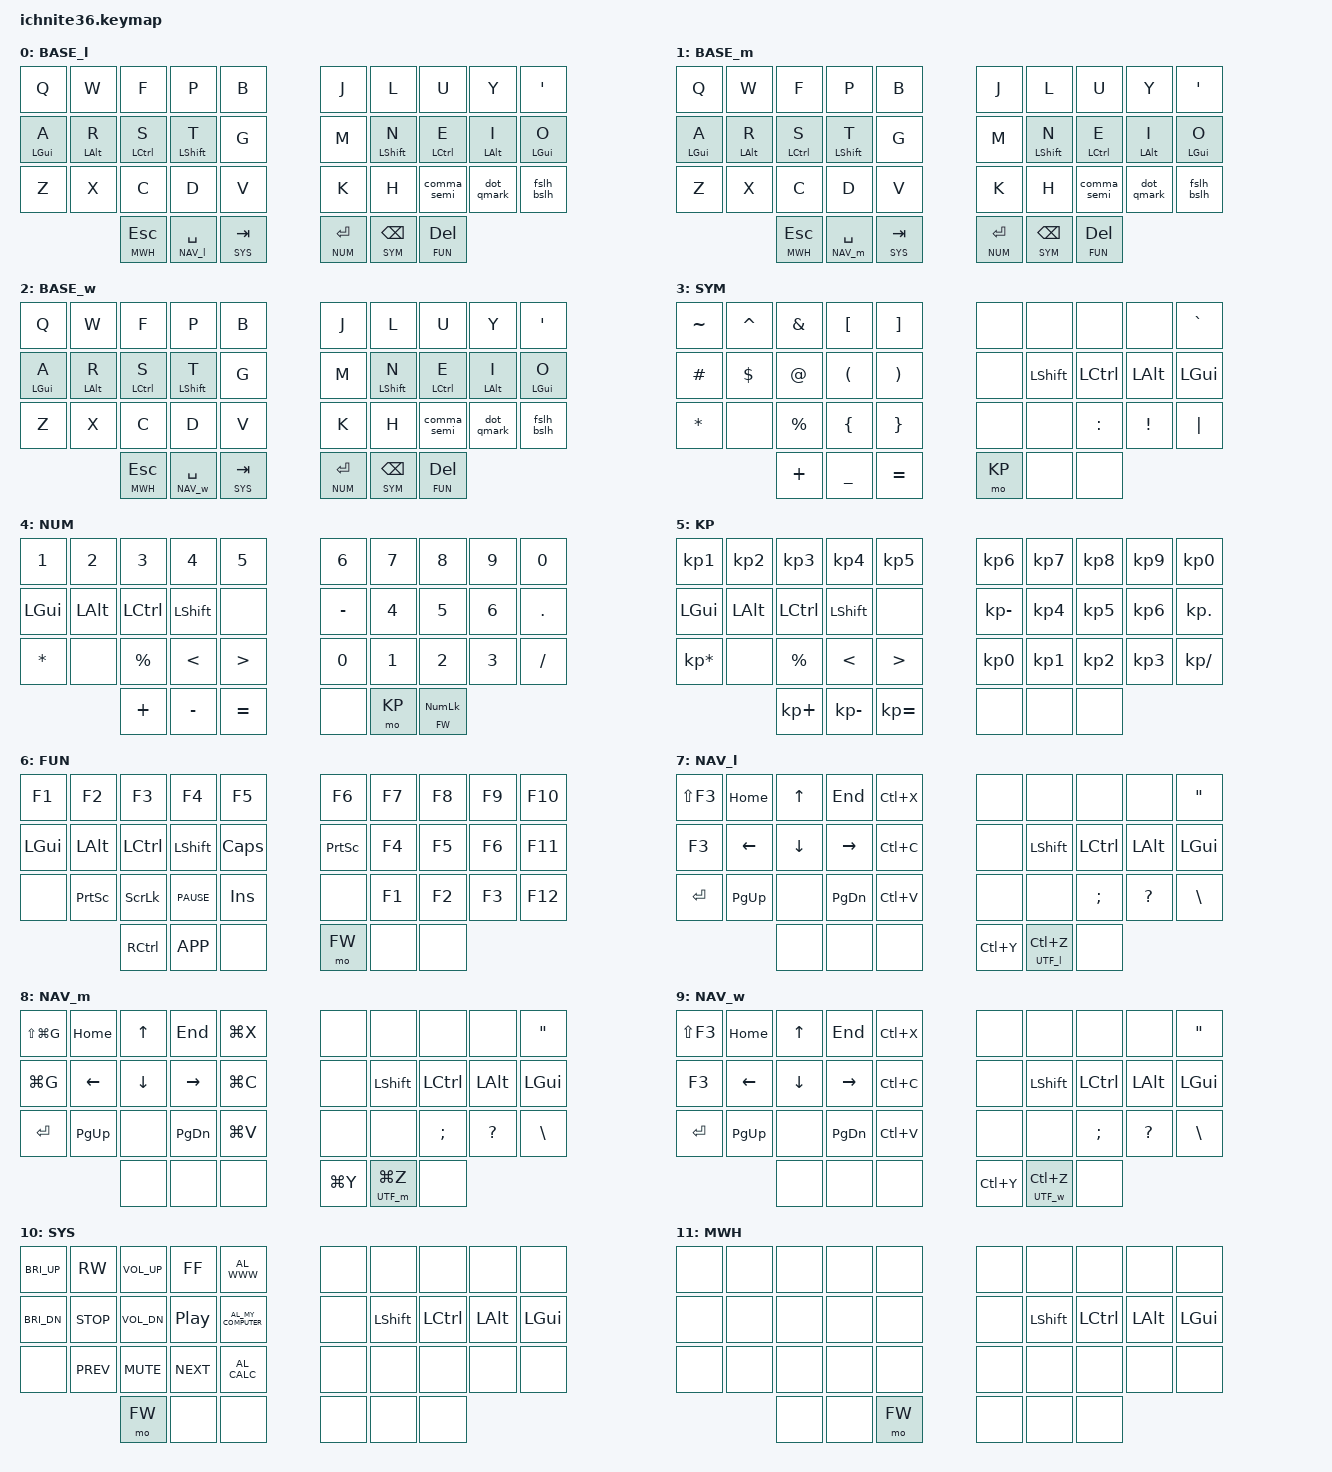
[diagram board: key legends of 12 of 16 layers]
#include <behaviors.dtsi>
#include <dt-bindings/zmk/bt.h>
#include <dt-bindings/zmk/keys.h>
#include <dt-bindings/zmk/outputs.h>

#define BASE_l 0
#define BASE_m 1
#define BASE_w 2
#define SYM 3
#define NUM 4
#define KP 5
#define FUN 6
#define NAV_l 7
#define NAV_m 8
#define NAV_w 9
#define SYS 10
#define MWH 11
#define UTF_l 12
#define UTF_m 13
#define UTF_w 14
#define FW 15

/ {
	chosen {
		zmk,matrix_transform = &default_transform;
	};
	keymap {
		compatible = "zmk,keymap";
		/* Colemak-DHm `base` layer
		┌────────┬────────┬──────────┬────────────┬──────────┐  ┌────────────┬───────────┬──────────┬────────┬────────┐
		│   q    │   w    │    f     │     p      │    b     │  │     j      │     l     │    u     │   y    │  '"    │
		├────────┼────────┼──────────┼────────────┼──────────┤  ├────────────┼───────────┼──────────┼────────┼────────┤
		│ a ⇩CMD │ r ⇩ALT │ s ⇩CTRL  │  t ⇩SHIFT  │    g     │  │     m      │ n ⇩SHIFT  │ e ⇩CTRL  │ i ⇩ALT │ o ⇩CMD │
		├────────┼────────┼──────────┼────────────┼──────────┤  ├────────────┼───────────┼──────────┼────────┼────────┤
		│   z    │   x    │    c     │     d      │    v     │  │     k      │     h     │   ,;     │  .?    │  /\    │
		└────────┴────────┼──────────┼────────────┼──────────┤  ├────────────┼───────────┼──────────┼────────┴────────┘
		                  │ ESC ⇩MWH │ SPACE ⇩NAV │ TAB ⇩SYS │  │ ENTER ⇩NUM │ BSPC ⇩SYM │ DEL ⇩FUN │                  
		                  └──────────┴────────────┴──────────┘  └────────────┴───────────┴──────────┘                   */
		BASE_l {
			bindings = <
			 &kp Q         &kp W         &kp F          &kp P             &kp B            &kp J         &kp L          &kp U          &kp Y         &kp SQT
			 &hrm LGUI A   &hrm LALT R   &hrm LCTRL S   &hrm LSHFT T      &kp G            &kp M         &hrm LSHFT N   &hrm LCTRL E   &hrm LALT I   &hrm LGUI O
			 &kp Z         &kp X         &kp C          &kp D             &kp V            &kp K         &kp H          &comma_semi    &dot_qmark    &fslh_bslh
			                             &lt MWH ESC    &lt NAV_l SPACE   &lt SYS TAB      &lt NUM RET   &lt SYM BSPC   &lt FUN DEL
			>;
		};
		BASE_m {
			bindings = <
			 &kp Q         &kp W         &kp F          &kp P             &kp B            &kp J         &kp L          &kp U          &kp Y         &kp SQT
			 &hrm LGUI A   &hrm LALT R   &hrm LCTRL S   &hrm LSHFT T      &kp G            &kp M         &hrm LSHFT N   &hrm LCTRL E   &hrm LALT I   &hrm LGUI O
			 &kp Z         &kp X         &kp C          &kp D             &kp V            &kp K         &kp H          &comma_semi    &dot_qmark    &fslh_bslh
			                             &lt MWH ESC    &lt NAV_m SPACE   &lt SYS TAB      &lt NUM RET   &lt SYM BSPC   &lt FUN DEL
			>;
		};
		BASE_w {
			bindings = <
			 &kp Q         &kp W         &kp F          &kp P             &kp B            &kp J         &kp L          &kp U          &kp Y         &kp SQT
			 &hrm LGUI A   &hrm LALT R   &hrm LCTRL S   &hrm LSHFT T      &kp G            &kp M         &hrm LSHFT N   &hrm LCTRL E   &hrm LALT I   &hrm LGUI O
			 &kp Z         &kp X         &kp C          &kp D             &kp V            &kp K         &kp H          &comma_semi    &dot_qmark    &fslh_bslh
			                             &lt MWH ESC    &lt NAV_w SPACE   &lt SYS TAB      &lt NUM RET   &lt SYM BSPC   &lt FUN DEL
			>;
		};
		/* Symbols
		┌───────┬───────┬───────┬───────┬───────┐  ┌───────┬───────┬───────┬───────┬───────┐
		│   ~   │   ^   │   &   │   [   │   ]   │  │       │       │       │       │   `   │
		├───────┼───────┼───────┼───────┼───────┤  ├───────┼───────┼───────┼───────┼───────┤
		│   #   │   $   │   @   │   (   │   )   │  │       │ SHIFT │ CTRL  │  ALT  │  CMD  │
		├───────┼───────┼───────┼───────┼───────┤  ├───────┼───────┼───────┼───────┼───────┤
		│   *   │       │   %   │   {   │   }   │  │       │       │   :   │   !   │ PIPE  │
		└───────┴───────┼───────┼───────┼───────┤  ├───────┼───────┼───────┼───────┴───────┘
		                │   +   │   _   │   =   │  │  ⇩KP  │       │       │                
		                └───────┴───────┴───────┘  └───────┴───────┴───────┘                 */
		SYM {
			bindings = <
			 &kp TILDE   &kp CARET   &kp AMPS    &kp LBKT    &kp RBKT       &none    &none       &none       &none      &kp GRAVE
			 &kp HASH    &kp DLLR    &kp AT      &kp LPAR    &kp RPAR       &none    &kp LSHFT   &kp LCTRL   &kp LALT   &kp LGUI
			 &kp STAR    &none       &kp PRCNT   &kp LBRC    &kp RBRC       &none    &none       &kp COLON   &kp EXCL   &kp PIPE
			                         &kp PLUS    &kp UNDER   &kp EQUAL      &mo KP   &none       &none
			>;
		};
		/* Numerals
		┌───────┬───────┬───────┬───────┬───────┐  ┌───────┬───────┬───────────┬───────┬───────┐
		│   1   │   2   │   3   │   4   │   5   │  │   6   │   7   │     8     │   9   │   0   │
		├───────┼───────┼───────┼───────┼───────┤  ├───────┼───────┼───────────┼───────┼───────┤
		│  CMD  │  ALT  │ CTRL  │ SHIFT │       │  │   -   │   4   │     5     │   6   │   .   │
		├───────┼───────┼───────┼───────┼───────┤  ├───────┼───────┼───────────┼───────┼───────┤
		│   *   │       │   %   │   <   │   >   │  │   0   │   1   │     2     │   3   │   /   │
		└───────┴───────┼───────┼───────┼───────┤  ├───────┼───────┼───────────┼───────┴───────┘
		                │   +   │   -   │   =   │  │       │  ⇩KP  │ NLOCK ⇩FW │                
		                └───────┴───────┴───────┘  └───────┴───────┴───────────┘                 */
		NUM {
			bindings = <
			 &kp N1     &kp N2     &kp N3      &kp N4      &kp N5         &kp N6      &kp N7   &kp N8          &kp N9   &kp N0
			 &kp LGUI   &kp LALT   &kp LCTRL   &kp LSHFT   &none          &kp MINUS   &kp N4   &kp N5          &kp N6   &kp DOT
			 &kp STAR   &none      &kp PRCNT   &kp LT      &kp GT         &kp N0      &kp N1   &kp N2          &kp N3   &kp FSLH
			                       &kp PLUS    &kp MINUS   &kp EQUAL      &none       &mo KP   &lt FW KP_NUM
			>;
		};
		/* Keypad numerals on `NUM+SYM` combo
		┌───────┬───────┬───────┬───────┬───────┐  ┌───────┬───────┬───────┬───────┬───────┐
		│  KP1  │  KP2  │  KP3  │  KP4  │  KP5  │  │  KP6  │  KP7  │  KP8  │  KP9  │  KP0  │
		├───────┼───────┼───────┼───────┼───────┤  ├───────┼───────┼───────┼───────┼───────┤
		│  CMD  │  ALT  │ CTRL  │ SHIFT │       │  │  KP-  │  KP4  │  KP5  │  KP6  │  KP.  │
		├───────┼───────┼───────┼───────┼───────┤  ├───────┼───────┼───────┼───────┼───────┤
		│  KP*  │       │   %   │   <   │   >   │  │  KP0  │  KP1  │  KP2  │  KP3  │  KP/  │
		└───────┴───────┼───────┼───────┼───────┤  ├───────┼───────┼───────┼───────┴───────┘
		                │  KP+  │  KP-  │  KP=  │  │       │       │       │                
		                └───────┴───────┴───────┘  └───────┴───────┴───────┘                 */
		KP {
			bindings = <
			 &kp KP_N1         &kp KP_N2   &kp KP_N3     &kp KP_N4      &kp KP_N5         &kp KP_N6      &kp KP_N7   &kp KP_N8   &kp KP_N9   &kp KP_N0
			 &kp LGUI          &kp LALT    &kp LCTRL     &kp LSHFT      &none             &kp KP_MINUS   &kp KP_N4   &kp KP_N5   &kp KP_N6   &kp KP_DOT
			 &kp KP_MULTIPLY   &none       &kp PRCNT     &kp LT         &kp GT            &kp KP_N0      &kp KP_N1   &kp KP_N2   &kp KP_N3   &kp KP_SLASH
			                               &kp KP_PLUS   &kp KP_MINUS   &kp KP_EQUAL      &none          &none       &none
			>;
		};
		/* Function keys
		┌───────┬───────┬───────┬───────┬───────┐  ┌───────┬───────┬───────┬───────┬───────┐
		│  F1   │  F2   │  F3   │  F4   │  F5   │  │  F6   │  F7   │  F8   │  F9   │  F10  │
		├───────┼───────┼───────┼───────┼───────┤  ├───────┼───────┼───────┼───────┼───────┤
		│  CMD  │  ALT  │ CTRL  │ SHIFT │ CAPS  │  │ PSCR  │  F4   │  F5   │  F6   │  F11  │
		├───────┼───────┼───────┼───────┼───────┤  ├───────┼───────┼───────┼───────┼───────┤
		│       │ PSCR  │ SLOCK │ PAUSE │  INS  │  │       │  F1   │  F2   │  F3   │  F12  │
		└───────┴───────┼───────┼───────┼───────┤  ├───────┼───────┼───────┼───────┴───────┘
		                │ rCTRL │  APP  │       │  │  ⇩FW  │       │       │                
		                └───────┴───────┴───────┘  └───────┴───────┴───────┘                 */
		FUN {
			bindings = <
			 &kp F1     &kp F2      &kp F3      &kp F4        &kp F5        &kp F6      &kp F7   &kp F8   &kp F9   &kp F10
			 &kp LGUI   &kp LALT    &kp LCTRL   &kp LSHFT     &kp CAPS      &kp PSCRN   &kp F4   &kp F5   &kp F6   &kp F11
			 &none      &kp PSCRN   &kp SLCK    &kp C_PAUSE   &kp INS       &none       &kp F1   &kp F2   &kp F3   &kp F12
			                        &kp RCTRL   &kp K_APP     &none         &mo FW      &none    &none
			>;
		};
		/* Navigation
		┌───────┬───────┬───────┬───────┬───────┐  ┌───────┬───────────┬───────┬───────┬───────┐
		│ FIND- │ HOME  │  UP   │  END  │  CUT  │  │       │           │       │       │   "   │
		├───────┼───────┼───────┼───────┼───────┤  ├───────┼───────────┼───────┼───────┼───────┤
		│ FIND+ │ LEFT  │ DOWN  │ RIGHT │ COPY  │  │       │   SHIFT   │ CTRL  │  ALT  │  CMD  │
		├───────┼───────┼───────┼───────┼───────┤  ├───────┼───────────┼───────┼───────┼───────┤
		│ ENTER │ PG_UP │       │ PG_DN │ PASTE │  │       │           │   ;   │   ?   │   \   │
		└───────┴───────┼───────┼───────┼───────┤  ├───────┼───────────┼───────┼───────┴───────┘
		                │       │       │       │  │ REDO  │ UNDO ⇩UTF │       │                
		                └───────┴───────┴───────┘  └───────┴───────────┴───────┘                 */
		NAV_l {
			bindings = <
			 &kp LS(F3)   &kp HOME    &kp UP     &kp END     &kp LC(X)      &none       &none             &none       &none       &kp DQT
			 &kp F3       &kp LEFT    &kp DOWN   &kp RIGHT   &kp LC(C)      &none       &kp LSHFT         &kp LCTRL   &kp LALT    &kp LGUI
			 &kp RET      &kp PG_UP   &none      &kp PG_DN   &kp LC(V)      &none       &none             &kp SEMI    &kp QMARK   &kp BSLH
			                          &none      &none       &none          &kp LC(Y)   &lt UTF_l LC(Z)   &none
			>;
		};
		NAV_m {
			bindings = <
			 &kp LS(LG(G))   &kp HOME    &kp UP     &kp END     &kp LG(X)      &none       &none             &none       &none       &kp DQT
			 &kp LG(G)       &kp LEFT    &kp DOWN   &kp RIGHT   &kp LG(C)      &none       &kp LSHFT         &kp LCTRL   &kp LALT    &kp LGUI
			 &kp RET         &kp PG_UP   &none      &kp PG_DN   &kp LG(V)      &none       &none             &kp SEMI    &kp QMARK   &kp BSLH
			                             &none      &none       &none          &kp LG(Y)   &lt UTF_m LG(Z)   &none
			>;
		};
		NAV_w {
			bindings = <
			 &kp LS(F3)   &kp HOME    &kp UP     &kp END     &kp LC(X)      &none       &none             &none       &none       &kp DQT
			 &kp F3       &kp LEFT    &kp DOWN   &kp RIGHT   &kp LC(C)      &none       &kp LSHFT         &kp LCTRL   &kp LALT    &kp LGUI
			 &kp RET      &kp PG_UP   &none      &kp PG_DN   &kp LC(V)      &none       &none             &kp SEMI    &kp QMARK   &kp BSLH
			                          &none      &none       &none          &kp LC(Y)   &lt UTF_w LC(Z)   &none
			>;
		};
		/* System/media keys
		┌───────┬───────┬───────┬───────┬────────┐  ┌───────┬───────┬───────┬───────┬───────┐
		│ BRI+  │  RWD  │ VOL+  │  FFW  │  WWW   │  │       │       │       │       │       │
		├───────┼───────┼───────┼───────┼────────┤  ├───────┼───────┼───────┼───────┼───────┤
		│ BRI-  │ STOP  │ VOL-  │ PLAY  │ MYCOMP │  │       │ SHIFT │ CTRL  │  ALT  │  CMD  │
		├───────┼───────┼───────┼───────┼────────┤  ├───────┼───────┼───────┼───────┼───────┤
		│       │ PREV  │ MUTE  │ NEXT  │ CALC   │  │       │       │       │       │       │
		└───────┴───────┼───────┼───────┼────────┤  ├───────┼───────┼───────┼───────┴───────┘
		                │  ⇩FW  │       │        │  │       │       │       │                
		                └───────┴───────┴────────┘  └───────┴───────┴───────┘                 */
		SYS {
			bindings = <
			 &kp C_BRI_UP   &kp C_RW     &kp C_VOL_UP   &kp C_FF     &kp C_AL_WWW              &none   &none       &none       &none      &none
			 &kp C_BRI_DN   &kp C_STOP   &kp C_VOL_DN   &kp C_PP     &kp C_AL_MY_COMPUTER      &none   &kp LSHFT   &kp LCTRL   &kp LALT   &kp LGUI
			 &none          &kp C_PREV   &kp C_MUTE     &kp C_NEXT   &kp C_AL_CALC             &none   &none       &none       &none      &none
			                             &mo FW         &none        &none                     &none   &none       &none
			>;
		};
		/* Mouse scrolling
		┌───────┬───────┬───────┬───────┬───────┐  ┌───────┬───────┬───────┬───────┬───────┐
		│       │       │ WH_U  │       │       │  │       │       │       │       │       │
		├───────┼───────┼───────┼───────┼───────┤  ├───────┼───────┼───────┼───────┼───────┤
		│       │ WH_L  │ WH_D  │ WH_R  │       │  │       │ SHIFT │ CTRL  │  ALT  │  CMD  │
		├───────┼───────┼───────┼───────┼───────┤  ├───────┼───────┼───────┼───────┼───────┤
		│       │       │       │       │       │  │       │       │       │       │       │
		└───────┴───────┼───────┼───────┼───────┤  ├───────┼───────┼───────┼───────┴───────┘
		                │       │       │  ⇩FW  │  │       │       │       │                
		                └───────┴───────┴───────┘  └───────┴───────┴───────┘                 */
		MWH {
			bindings = <
			 &none   &none   &none   &none   &none       &none   &none       &none       &none      &none
			 &none   &none   &none   &none   &none       &none   &kp LSHFT   &kp LCTRL   &kp LALT   &kp LGUI
			 &none   &none   &none   &none   &none       &none   &none       &none       &none      &none
			                 &none   &none   &mo FW      &none   &none       &none
			>;
		};
		/* Unicode Symbols on `NAV>SYM`
		┌───────┬───────┬───────┬───────┬───────┐  ┌───────┬───────┬───────┬───────┬───────┐
		│       │       │   °   │   √   │       │  │       │   μ   │   Δ   │   ε   │       │
		├───────┼───────┼───────┼───────┼───────┤  ├───────┼───────┼───────┼───────┼───────┤
		│   ∞   │   €   │       │   ²   │   ³   │  │       │   π   │   φ   │   θ   │       │
		├───────┼───────┼───────┼───────┼───────┤  ├───────┼───────┼───────┼───────┼───────┤
		│   ×   │       │   ≈   │   ≤   │   ≥   │  │   λ   │   α   │   β   │   ¿   │   ÷   │
		└───────┴───────┼───────┼───────┼───────┤  ├───────┼───────┼───────┼───────┴───────┘
		                │   ±   │       │   ≠   │  │       │       │       │                
		                └───────┴───────┴───────┘  └───────┴───────┴───────┘                 */
		UTF_l {
			bindings = <
			 &none      &none      &u00b0_L   &u221a_L   &none         &none      &u03bc_L   &u0394_L   &u03b5_L   &none
			 &u221e_L   &u20ac_L   &none      &u00b2_L   &u00b3_L      &none      &u03c0_L   &u03c6_L   &u03b8_L   &none
			 &u00d7_L   &none      &u2248_L   &u2264_L   &u2265_L      &u03bb_L   &u03b1_L   &u03b2_L   &u00bf_L   &u00f7_L
			                       &u00b1_L   &none      &u2260_L      &none      &none      &none
			>;
		};
		UTF_m {
			bindings = <
			 &none      &none      &u00b0_M   &u221a_M   &none         &none      &u03bc_M   &u0394_M   &u03b5_M   &none
			 &u221e_M   &u20ac_M   &none      &u00b2_M   &u00b3_M      &none      &u03c0_M   &u03c6_M   &u03b8_M   &none
			 &u00d7_M   &none      &u2248_M   &u2264_M   &u2265_M      &u03bb_M   &u03b1_M   &u03b2_M   &u00bf_M   &u00f7_M
			                       &u00b1_M   &none      &u2260_M      &none      &none      &none
			>;
		};
		UTF_w {
			bindings = <
			 &none      &none      &u00b0_W   &u221a_W   &none         &none      &u03bc_W   &u0394_W   &u03b5_W   &none
			 &u221e_W   &u20ac_W   &none      &u00b2_W   &u00b3_W      &none      &u03c0_W   &u03c6_W   &u03b8_W   &none
			 &u00d7_W   &none      &u2248_W   &u2264_W   &u2265_W      &u03bb_W   &u03b1_W   &u03b2_W   &u00bf_W   &u00f7_W
			                       &u00b1_W   &none      &u2260_W      &none      &none      &none
			>;
		};
		/* Firmware on `NUM+FUN` or `MWH+SYS` combo
		┌───────┬───────┬───────┬────────┬───────┐  ┌───────┬───────┬───────┬───────┬───────┐
		│  BT1  │  BT2  │  BT3  │  BT4   │  BT5  │  │  USB  │       │       │       │ BTCLR │
		├───────┼───────┼───────┼────────┼───────┤  ├───────┼───────┼───────┼───────┼───────┤
		│       │ @win  │ @mac  │ @linux │       │  │       │       │       │       │       │
		├───────┼───────┼───────┼────────┼───────┤  ├───────┼───────┼───────┼───────┼───────┤
		│       │       │       │        │       │  │       │       │       │       │       │
		└───────┴───────┼───────┼────────┼───────┤  ├───────┼───────┼───────┼───────┴───────┘
		                │ DEBUG │ RESET  │ BOOTL │  │ BOOTL │ RESET │ DEBUG │                
		                └───────┴────────┴───────┘  └───────┴───────┴───────┘                 */
		FW {
			bindings = <
			 &bt1    &bt2         &bt3         &bt4         &bt5             &out OUT_USB   &none    &none   &none   &bt BT_CLR
			 &none   &to BASE_w   &to BASE_m   &to BASE_l   &none            &none          &none    &none   &none   &none
			 &none   &none        &none        &none        &none            &none          &none    &none   &none   &none
			                      &none        &reset       &bootloader      &bootloader    &reset   &none
			>;
		};
	};
	behaviors {
		hrm: modtap {
			compatible = "zmk,behavior-hold-tap";
			label = "HOMEROWMOD";
			#binding-cells = <2>;
			bindings = <&kp>, <&kp>;
		};
		comma_semi: comma_semi {
			compatible = "zmk,behavior-mod-morph";
			label = "shift-morph COMMA SEMI";
			#binding-cells = <0>;
			bindings = <&kp COMMA>, <&kp SEMI>;
			mods = <(MOD_LSFT|MOD_RSFT)>;
		};
		dot_qmark: dot_qmark {
			compatible = "zmk,behavior-mod-morph";
			label = "shift-morph DOT QMARK";
			#binding-cells = <0>;
			bindings = <&kp DOT>, <&kp QMARK>;
			mods = <(MOD_LSFT|MOD_RSFT)>;
		};
		fslh_bslh: fslh_bslh {
			compatible = "zmk,behavior-mod-morph";
			label = "shift-morph FSLH BSLH";
			#binding-cells = <0>;
			bindings = <&kp FSLH>, <&kp BSLH>;
			mods = <(MOD_LSFT|MOD_RSFT)>;
		};
		u00b0_L: u00b0_L {
			compatible = "zmk,behavior-macro";
			label = "Linux ° macro";
			#binding-cells = <0>;
			bindings = <&macro_tap &kp LC(LS(U)) &kp N0 &kp N0 &kp B &kp N0 &kp SPACE>;
			tap-ms = <30>;
			wait-ms = <0>;
		};
		u221a_L: u221a_L {
			compatible = "zmk,behavior-macro";
			label = "Linux √ macro";
			#binding-cells = <0>;
			bindings = <&macro_tap &kp LC(LS(U)) &kp N2 &kp N2 &kp N1 &kp A &kp SPACE>;
			tap-ms = <30>;
			wait-ms = <0>;
		};
		u03bc_L: u03bc_L {
			compatible = "zmk,behavior-macro";
			label = "Linux μ macro";
			#binding-cells = <0>;
			bindings = <&macro_tap &kp LC(LS(U)) &kp N0 &kp N3 &kp B &kp C &kp SPACE>;
			tap-ms = <30>;
			wait-ms = <0>;
		};
		u0394_L: u0394_L {
			compatible = "zmk,behavior-macro";
			label = "Linux Δ macro";
			#binding-cells = <0>;
			bindings = <&macro_tap &kp LC(LS(U)) &kp N0 &kp N3 &kp N9 &kp N4 &kp SPACE>;
			tap-ms = <30>;
			wait-ms = <0>;
		};
		u03b5_L: u03b5_L {
			compatible = "zmk,behavior-macro";
			label = "Linux ε macro";
			#binding-cells = <0>;
			bindings = <&macro_tap &kp LC(LS(U)) &kp N0 &kp N3 &kp B &kp N5 &kp SPACE>;
			tap-ms = <30>;
			wait-ms = <0>;
		};
		u221e_L: u221e_L {
			compatible = "zmk,behavior-macro";
			label = "Linux ∞ macro";
			#binding-cells = <0>;
			bindings = <&macro_tap &kp LC(LS(U)) &kp N2 &kp N2 &kp N1 &kp E &kp SPACE>;
			tap-ms = <30>;
			wait-ms = <0>;
		};
		u20ac_L: u20ac_L {
			compatible = "zmk,behavior-macro";
			label = "Linux € macro";
			#binding-cells = <0>;
			bindings = <&macro_tap &kp LC(LS(U)) &kp N2 &kp N0 &kp A &kp C &kp SPACE>;
			tap-ms = <30>;
			wait-ms = <0>;
		};
		u00b2_L: u00b2_L {
			compatible = "zmk,behavior-macro";
			label = "Linux ² macro";
			#binding-cells = <0>;
			bindings = <&macro_tap &kp LC(LS(U)) &kp N0 &kp N0 &kp B &kp N2 &kp SPACE>;
			tap-ms = <30>;
			wait-ms = <0>;
		};
		u00b3_L: u00b3_L {
			compatible = "zmk,behavior-macro";
			label = "Linux ³ macro";
			#binding-cells = <0>;
			bindings = <&macro_tap &kp LC(LS(U)) &kp N0 &kp N0 &kp B &kp N3 &kp SPACE>;
			tap-ms = <30>;
			wait-ms = <0>;
		};
		u03c0_L: u03c0_L {
			compatible = "zmk,behavior-macro";
			label = "Linux π macro";
			#binding-cells = <0>;
			bindings = <&macro_tap &kp LC(LS(U)) &kp N0 &kp N3 &kp C &kp N0 &kp SPACE>;
			tap-ms = <30>;
			wait-ms = <0>;
		};
		u03c6_L: u03c6_L {
			compatible = "zmk,behavior-macro";
			label = "Linux φ macro";
			#binding-cells = <0>;
			bindings = <&macro_tap &kp LC(LS(U)) &kp N0 &kp N3 &kp C &kp N6 &kp SPACE>;
			tap-ms = <30>;
			wait-ms = <0>;
		};
		u03b8_L: u03b8_L {
			compatible = "zmk,behavior-macro";
			label = "Linux θ macro";
			#binding-cells = <0>;
			bindings = <&macro_tap &kp LC(LS(U)) &kp N0 &kp N3 &kp B &kp N8 &kp SPACE>;
			tap-ms = <30>;
			wait-ms = <0>;
		};
		u00d7_L: u00d7_L {
			compatible = "zmk,behavior-macro";
			label = "Linux × macro";
			#binding-cells = <0>;
			bindings = <&macro_tap &kp LC(LS(U)) &kp N0 &kp N0 &kp D &kp N7 &kp SPACE>;
			tap-ms = <30>;
			wait-ms = <0>;
		};
		u2248_L: u2248_L {
			compatible = "zmk,behavior-macro";
			label = "Linux ≈ macro";
			#binding-cells = <0>;
			bindings = <&macro_tap &kp LC(LS(U)) &kp N2 &kp N2 &kp N4 &kp N8 &kp SPACE>;
			tap-ms = <30>;
			wait-ms = <0>;
		};
		u2264_L: u2264_L {
			compatible = "zmk,behavior-macro";
			label = "Linux ≤ macro";
			#binding-cells = <0>;
			bindings = <&macro_tap &kp LC(LS(U)) &kp N2 &kp N2 &kp N6 &kp N4 &kp SPACE>;
			tap-ms = <30>;
			wait-ms = <0>;
		};
		u2265_L: u2265_L {
			compatible = "zmk,behavior-macro";
			label = "Linux ≥ macro";
			#binding-cells = <0>;
			bindings = <&macro_tap &kp LC(LS(U)) &kp N2 &kp N2 &kp N6 &kp N5 &kp SPACE>;
			tap-ms = <30>;
			wait-ms = <0>;
		};
		u03bb_L: u03bb_L {
			compatible = "zmk,behavior-macro";
			label = "Linux λ macro";
			#binding-cells = <0>;
			bindings = <&macro_tap &kp LC(LS(U)) &kp N0 &kp N3 &kp B &kp B &kp SPACE>;
			tap-ms = <30>;
			wait-ms = <0>;
		};
		u03b1_L: u03b1_L {
			compatible = "zmk,behavior-macro";
			label = "Linux α macro";
			#binding-cells = <0>;
			bindings = <&macro_tap &kp LC(LS(U)) &kp N0 &kp N3 &kp B &kp N1 &kp SPACE>;
			tap-ms = <30>;
			wait-ms = <0>;
		};
		u03b2_L: u03b2_L {
			compatible = "zmk,behavior-macro";
			label = "Linux β macro";
			#binding-cells = <0>;
			bindings = <&macro_tap &kp LC(LS(U)) &kp N0 &kp N3 &kp B &kp N2 &kp SPACE>;
			tap-ms = <30>;
			wait-ms = <0>;
		};
		u00bf_L: u00bf_L {
			compatible = "zmk,behavior-macro";
			label = "Linux ¿ macro";
			#binding-cells = <0>;
			bindings = <&macro_tap &kp LC(LS(U)) &kp N0 &kp N0 &kp B &kp F &kp SPACE>;
			tap-ms = <30>;
			wait-ms = <0>;
		};
		u00f7_L: u00f7_L {
			compatible = "zmk,behavior-macro";
			label = "Linux ÷ macro";
			#binding-cells = <0>;
			bindings = <&macro_tap &kp LC(LS(U)) &kp N0 &kp N0 &kp F &kp N7 &kp SPACE>;
			tap-ms = <30>;
			wait-ms = <0>;
		};
		u00b1_L: u00b1_L {
			compatible = "zmk,behavior-macro";
			label = "Linux ± macro";
			#binding-cells = <0>;
			bindings = <&macro_tap &kp LC(LS(U)) &kp N0 &kp N0 &kp B &kp N1 &kp SPACE>;
			tap-ms = <30>;
			wait-ms = <0>;
		};
		u2260_L: u2260_L {
			compatible = "zmk,behavior-macro";
			label = "Linux ≠ macro";
			#binding-cells = <0>;
			bindings = <&macro_tap &kp LC(LS(U)) &kp N2 &kp N2 &kp N6 &kp N0 &kp SPACE>;
			tap-ms = <30>;
			wait-ms = <0>;
		};
		u00b0_M: u00b0_M {
			compatible = "zmk,behavior-macro";
			label = "Mac ° macro";
			#binding-cells = <0>;
			bindings = <&macro_press &kp LALT>, <&macro_tap &kp N0 &kp N0 &kp B &kp N0>, <&macro_release &kp LALT>;
			tap-ms = <30>;
			wait-ms = <30>;
		};
		u221a_M: u221a_M {
			compatible = "zmk,behavior-macro";
			label = "Mac √ macro";
			#binding-cells = <0>;
			bindings = <&macro_press &kp LALT>, <&macro_tap &kp N2 &kp N2 &kp N1 &kp A>, <&macro_release &kp LALT>;
			tap-ms = <30>;
			wait-ms = <30>;
		};
		u03bc_M: u03bc_M {
			compatible = "zmk,behavior-macro";
			label = "Mac μ macro";
			#binding-cells = <0>;
			bindings = <&macro_press &kp LALT>, <&macro_tap &kp N0 &kp N3 &kp B &kp C>, <&macro_release &kp LALT>;
			tap-ms = <30>;
			wait-ms = <30>;
		};
		u0394_M: u0394_M {
			compatible = "zmk,behavior-macro";
			label = "Mac Δ macro";
			#binding-cells = <0>;
			bindings = <&macro_press &kp LALT>, <&macro_tap &kp N0 &kp N3 &kp N9 &kp N4>, <&macro_release &kp LALT>;
			tap-ms = <30>;
			wait-ms = <30>;
		};
		u03b5_M: u03b5_M {
			compatible = "zmk,behavior-macro";
			label = "Mac ε macro";
			#binding-cells = <0>;
			bindings = <&macro_press &kp LALT>, <&macro_tap &kp N0 &kp N3 &kp B &kp N5>, <&macro_release &kp LALT>;
			tap-ms = <30>;
			wait-ms = <30>;
		};
		u221e_M: u221e_M {
			compatible = "zmk,behavior-macro";
			label = "Mac ∞ macro";
			#binding-cells = <0>;
			bindings = <&macro_press &kp LALT>, <&macro_tap &kp N2 &kp N2 &kp N1 &kp E>, <&macro_release &kp LALT>;
			tap-ms = <30>;
			wait-ms = <30>;
		};
		u20ac_M: u20ac_M {
			compatible = "zmk,behavior-macro";
			label = "Mac € macro";
			#binding-cells = <0>;
			bindings = <&macro_press &kp LALT>, <&macro_tap &kp N2 &kp N0 &kp A &kp C>, <&macro_release &kp LALT>;
			tap-ms = <30>;
			wait-ms = <30>;
		};
		u00b2_M: u00b2_M {
			compatible = "zmk,behavior-macro";
			label = "Mac ² macro";
			#binding-cells = <0>;
			bindings = <&macro_press &kp LALT>, <&macro_tap &kp N0 &kp N0 &kp B &kp N2>, <&macro_release &kp LALT>;
			tap-ms = <30>;
			wait-ms = <30>;
		};
		u00b3_M: u00b3_M {
			compatible = "zmk,behavior-macro";
			label = "Mac ³ macro";
			#binding-cells = <0>;
			bindings = <&macro_press &kp LALT>, <&macro_tap &kp N0 &kp N0 &kp B &kp N3>, <&macro_release &kp LALT>;
			tap-ms = <30>;
			wait-ms = <30>;
		};
		u03c0_M: u03c0_M {
			compatible = "zmk,behavior-macro";
			label = "Mac π macro";
			#binding-cells = <0>;
			bindings = <&macro_press &kp LALT>, <&macro_tap &kp N0 &kp N3 &kp C &kp N0>, <&macro_release &kp LALT>;
			tap-ms = <30>;
			wait-ms = <30>;
		};
		u03c6_M: u03c6_M {
			compatible = "zmk,behavior-macro";
			label = "Mac φ macro";
			#binding-cells = <0>;
			bindings = <&macro_press &kp LALT>, <&macro_tap &kp N0 &kp N3 &kp C &kp N6>, <&macro_release &kp LALT>;
			tap-ms = <30>;
			wait-ms = <30>;
		};
		u03b8_M: u03b8_M {
			compatible = "zmk,behavior-macro";
			label = "Mac θ macro";
			#binding-cells = <0>;
			bindings = <&macro_press &kp LALT>, <&macro_tap &kp N0 &kp N3 &kp B &kp N8>, <&macro_release &kp LALT>;
			tap-ms = <30>;
			wait-ms = <30>;
		};
		u00d7_M: u00d7_M {
			compatible = "zmk,behavior-macro";
			label = "Mac × macro";
			#binding-cells = <0>;
			bindings = <&macro_press &kp LALT>, <&macro_tap &kp N0 &kp N0 &kp D &kp N7>, <&macro_release &kp LALT>;
			tap-ms = <30>;
			wait-ms = <30>;
		};
		u2248_M: u2248_M {
			compatible = "zmk,behavior-macro";
			label = "Mac ≈ macro";
			#binding-cells = <0>;
			bindings = <&macro_press &kp LALT>, <&macro_tap &kp N2 &kp N2 &kp N4 &kp N8>, <&macro_release &kp LALT>;
			tap-ms = <30>;
			wait-ms = <30>;
		};
		u2264_M: u2264_M {
			compatible = "zmk,behavior-macro";
			label = "Mac ≤ macro";
			#binding-cells = <0>;
			bindings = <&macro_press &kp LALT>, <&macro_tap &kp N2 &kp N2 &kp N6 &kp N4>, <&macro_release &kp LALT>;
			tap-ms = <30>;
			wait-ms = <30>;
		};
		u2265_M: u2265_M {
			compatible = "zmk,behavior-macro";
			label = "Mac ≥ macro";
			#binding-cells = <0>;
			bindings = <&macro_press &kp LALT>, <&macro_tap &kp N2 &kp N2 &kp N6 &kp N5>, <&macro_release &kp LALT>;
			tap-ms = <30>;
			wait-ms = <30>;
		};
		u03bb_M: u03bb_M {
			compatible = "zmk,behavior-macro";
			label = "Mac λ macro";
			#binding-cells = <0>;
			bindings = <&macro_press &kp LALT>, <&macro_tap &kp N0 &kp N3 &kp B &kp B>, <&macro_release &kp LALT>;
			tap-ms = <30>;
			wait-ms = <30>;
		};
		u03b1_M: u03b1_M {
			compatible = "zmk,behavior-macro";
			label = "Mac α macro";
			#binding-cells = <0>;
			bindings = <&macro_press &kp LALT>, <&macro_tap &kp N0 &kp N3 &kp B &kp N1>, <&macro_release &kp LALT>;
			tap-ms = <30>;
			wait-ms = <30>;
		};
		u03b2_M: u03b2_M {
			compatible = "zmk,behavior-macro";
			label = "Mac β macro";
			#binding-cells = <0>;
			bindings = <&macro_press &kp LALT>, <&macro_tap &kp N0 &kp N3 &kp B &kp N2>, <&macro_release &kp LALT>;
			tap-ms = <30>;
			wait-ms = <30>;
		};
		u00bf_M: u00bf_M {
			compatible = "zmk,behavior-macro";
			label = "Mac ¿ macro";
			#binding-cells = <0>;
			bindings = <&macro_press &kp LALT>, <&macro_tap &kp N0 &kp N0 &kp B &kp F>, <&macro_release &kp LALT>;
			tap-ms = <30>;
			wait-ms = <30>;
		};
		u00f7_M: u00f7_M {
			compatible = "zmk,behavior-macro";
			label = "Mac ÷ macro";
			#binding-cells = <0>;
			bindings = <&macro_press &kp LALT>, <&macro_tap &kp N0 &kp N0 &kp F &kp N7>, <&macro_release &kp LALT>;
			tap-ms = <30>;
			wait-ms = <30>;
		};
		u00b1_M: u00b1_M {
			compatible = "zmk,behavior-macro";
			label = "Mac ± macro";
			#binding-cells = <0>;
			bindings = <&macro_press &kp LALT>, <&macro_tap &kp N0 &kp N0 &kp B &kp N1>, <&macro_release &kp LALT>;
			tap-ms = <30>;
			wait-ms = <30>;
		};
		u2260_M: u2260_M {
			compatible = "zmk,behavior-macro";
			label = "Mac ≠ macro";
			#binding-cells = <0>;
			bindings = <&macro_press &kp LALT>, <&macro_tap &kp N2 &kp N2 &kp N6 &kp N0>, <&macro_release &kp LALT>;
			tap-ms = <30>;
			wait-ms = <30>;
		};
		u00b0_W: u00b0_W {
			compatible = "zmk,behavior-macro";
			label = "Wincompose ° macro";
			#binding-cells = <0>;
			bindings = <&macro_tap &kp RALT &kp U &kp N0 &kp N0 &kp B &kp N0 &kp RET>;
		};
		u221a_W: u221a_W {
			compatible = "zmk,behavior-macro";
			label = "Wincompose √ macro";
			#binding-cells = <0>;
			bindings = <&macro_tap &kp RALT &kp U &kp N2 &kp N2 &kp N1 &kp A &kp RET>;
		};
		u03bc_W: u03bc_W {
			compatible = "zmk,behavior-macro";
			label = "Wincompose μ macro";
			#binding-cells = <0>;
			bindings = <&macro_tap &kp RALT &kp U &kp N0 &kp N3 &kp B &kp C &kp RET>;
		};
		u0394_W: u0394_W {
			compatible = "zmk,behavior-macro";
			label = "Wincompose Δ macro";
			#binding-cells = <0>;
			bindings = <&macro_tap &kp RALT &kp U &kp N0 &kp N3 &kp N9 &kp N4 &kp RET>;
		};
		u03b5_W: u03b5_W {
			compatible = "zmk,behavior-macro";
			label = "Wincompose ε macro";
			#binding-cells = <0>;
			bindings = <&macro_tap &kp RALT &kp U &kp N0 &kp N3 &kp B &kp N5 &kp RET>;
		};
		u221e_W: u221e_W {
			compatible = "zmk,behavior-macro";
			label = "Wincompose ∞ macro";
			#binding-cells = <0>;
			bindings = <&macro_tap &kp RALT &kp U &kp N2 &kp N2 &kp N1 &kp E &kp RET>;
		};
		u20ac_W: u20ac_W {
			compatible = "zmk,behavior-macro";
			label = "Wincompose € macro";
			#binding-cells = <0>;
			bindings = <&macro_tap &kp RALT &kp U &kp N2 &kp N0 &kp A &kp C &kp RET>;
		};
		u00b2_W: u00b2_W {
			compatible = "zmk,behavior-macro";
			label = "Wincompose ² macro";
			#binding-cells = <0>;
			bindings = <&macro_tap &kp RALT &kp U &kp N0 &kp N0 &kp B &kp N2 &kp RET>;
		};
		u00b3_W: u00b3_W {
			compatible = "zmk,behavior-macro";
			label = "Wincompose ³ macro";
			#binding-cells = <0>;
			bindings = <&macro_tap &kp RALT &kp U &kp N0 &kp N0 &kp B &kp N3 &kp RET>;
		};
		u03c0_W: u03c0_W {
			compatible = "zmk,behavior-macro";
			label = "Wincompose π macro";
			#binding-cells = <0>;
			bindings = <&macro_tap &kp RALT &kp U &kp N0 &kp N3 &kp C &kp N0 &kp RET>;
		};
		u03c6_W: u03c6_W {
			compatible = "zmk,behavior-macro";
			label = "Wincompose φ macro";
			#binding-cells = <0>;
			bindings = <&macro_tap &kp RALT &kp U &kp N0 &kp N3 &kp C &kp N6 &kp RET>;
		};
		u03b8_W: u03b8_W {
			compatible = "zmk,behavior-macro";
			label = "Wincompose θ macro";
			#binding-cells = <0>;
			bindings = <&macro_tap &kp RALT &kp U &kp N0 &kp N3 &kp B &kp N8 &kp RET>;
		};
		u00d7_W: u00d7_W {
			compatible = "zmk,behavior-macro";
			label = "Wincompose × macro";
			#binding-cells = <0>;
			bindings = <&macro_tap &kp RALT &kp U &kp N0 &kp N0 &kp D &kp N7 &kp RET>;
		};
		u2248_W: u2248_W {
			compatible = "zmk,behavior-macro";
			label = "Wincompose ≈ macro";
			#binding-cells = <0>;
			bindings = <&macro_tap &kp RALT &kp U &kp N2 &kp N2 &kp N4 &kp N8 &kp RET>;
		};
		u2264_W: u2264_W {
			compatible = "zmk,behavior-macro";
			label = "Wincompose ≤ macro";
			#binding-cells = <0>;
			bindings = <&macro_tap &kp RALT &kp U &kp N2 &kp N2 &kp N6 &kp N4 &kp RET>;
		};
		u2265_W: u2265_W {
			compatible = "zmk,behavior-macro";
			label = "Wincompose ≥ macro";
			#binding-cells = <0>;
			bindings = <&macro_tap &kp RALT &kp U &kp N2 &kp N2 &kp N6 &kp N5 &kp RET>;
		};
		u03bb_W: u03bb_W {
			compatible = "zmk,behavior-macro";
			label = "Wincompose λ macro";
			#binding-cells = <0>;
			bindings = <&macro_tap &kp RALT &kp U &kp N0 &kp N3 &kp B &kp B &kp RET>;
		};
		u03b1_W: u03b1_W {
			compatible = "zmk,behavior-macro";
			label = "Wincompose α macro";
			#binding-cells = <0>;
			bindings = <&macro_tap &kp RALT &kp U &kp N0 &kp N3 &kp B &kp N1 &kp RET>;
		};
		u03b2_W: u03b2_W {
			compatible = "zmk,behavior-macro";
			label = "Wincompose β macro";
			#binding-cells = <0>;
			bindings = <&macro_tap &kp RALT &kp U &kp N0 &kp N3 &kp B &kp N2 &kp RET>;
		};
		u00bf_W: u00bf_W {
			compatible = "zmk,behavior-macro";
			label = "Wincompose ¿ macro";
			#binding-cells = <0>;
			bindings = <&macro_tap &kp RALT &kp U &kp N0 &kp N0 &kp B &kp F &kp RET>;
		};
		u00f7_W: u00f7_W {
			compatible = "zmk,behavior-macro";
			label = "Wincompose ÷ macro";
			#binding-cells = <0>;
			bindings = <&macro_tap &kp RALT &kp U &kp N0 &kp N0 &kp F &kp N7 &kp RET>;
		};
		u00b1_W: u00b1_W {
			compatible = "zmk,behavior-macro";
			label = "Wincompose ± macro";
			#binding-cells = <0>;
			bindings = <&macro_tap &kp RALT &kp U &kp N0 &kp N0 &kp B &kp N1 &kp RET>;
		};
		u2260_W: u2260_W {
			compatible = "zmk,behavior-macro";
			label = "Wincompose ≠ macro";
			#binding-cells = <0>;
			bindings = <&macro_tap &kp RALT &kp U &kp N2 &kp N2 &kp N6 &kp N0 &kp RET>;
		};
		bt1: bt1 {
			compatible = "zmk,behavior-macro";
			label = "macro_bt1";
			#binding-cells = <0>;
			bindings = <&bt BT_SEL 0>, <&out OUT_BLE>, <&to (-1)>;
		};
		bt2: bt2 {
			compatible = "zmk,behavior-macro";
			label = "macro_bt2";
			#binding-cells = <0>;
			bindings = <&bt BT_SEL 1>, <&out OUT_BLE>, <&to (-1)>;
		};
		bt3: bt3 {
			compatible = "zmk,behavior-macro";
			label = "macro_bt3";
			#binding-cells = <0>;
			bindings = <&bt BT_SEL 2>, <&out OUT_BLE>, <&to (-1)>;
		};
		bt4: bt4 {
			compatible = "zmk,behavior-macro";
			label = "macro_bt4";
			#binding-cells = <0>;
			bindings = <&bt BT_SEL 3>, <&out OUT_BLE>, <&to (-1)>;
		};
		bt5: bt5 {
			compatible = "zmk,behavior-macro";
			label = "macro_bt5";
			#binding-cells = <0>;
			bindings = <&bt BT_SEL 4>, <&out OUT_BLE>, <&to (-1)>;
		};
	};
};

&lt {
	flavor = "hold-preferred";
	tapping-term-ms = <150>;
	quick-tap-ms = <200>;
};

&hrm {
	flavor = "tap-preferred";
	tapping-term-ms = <150>;
	quick-tap-ms = <200>;
};

